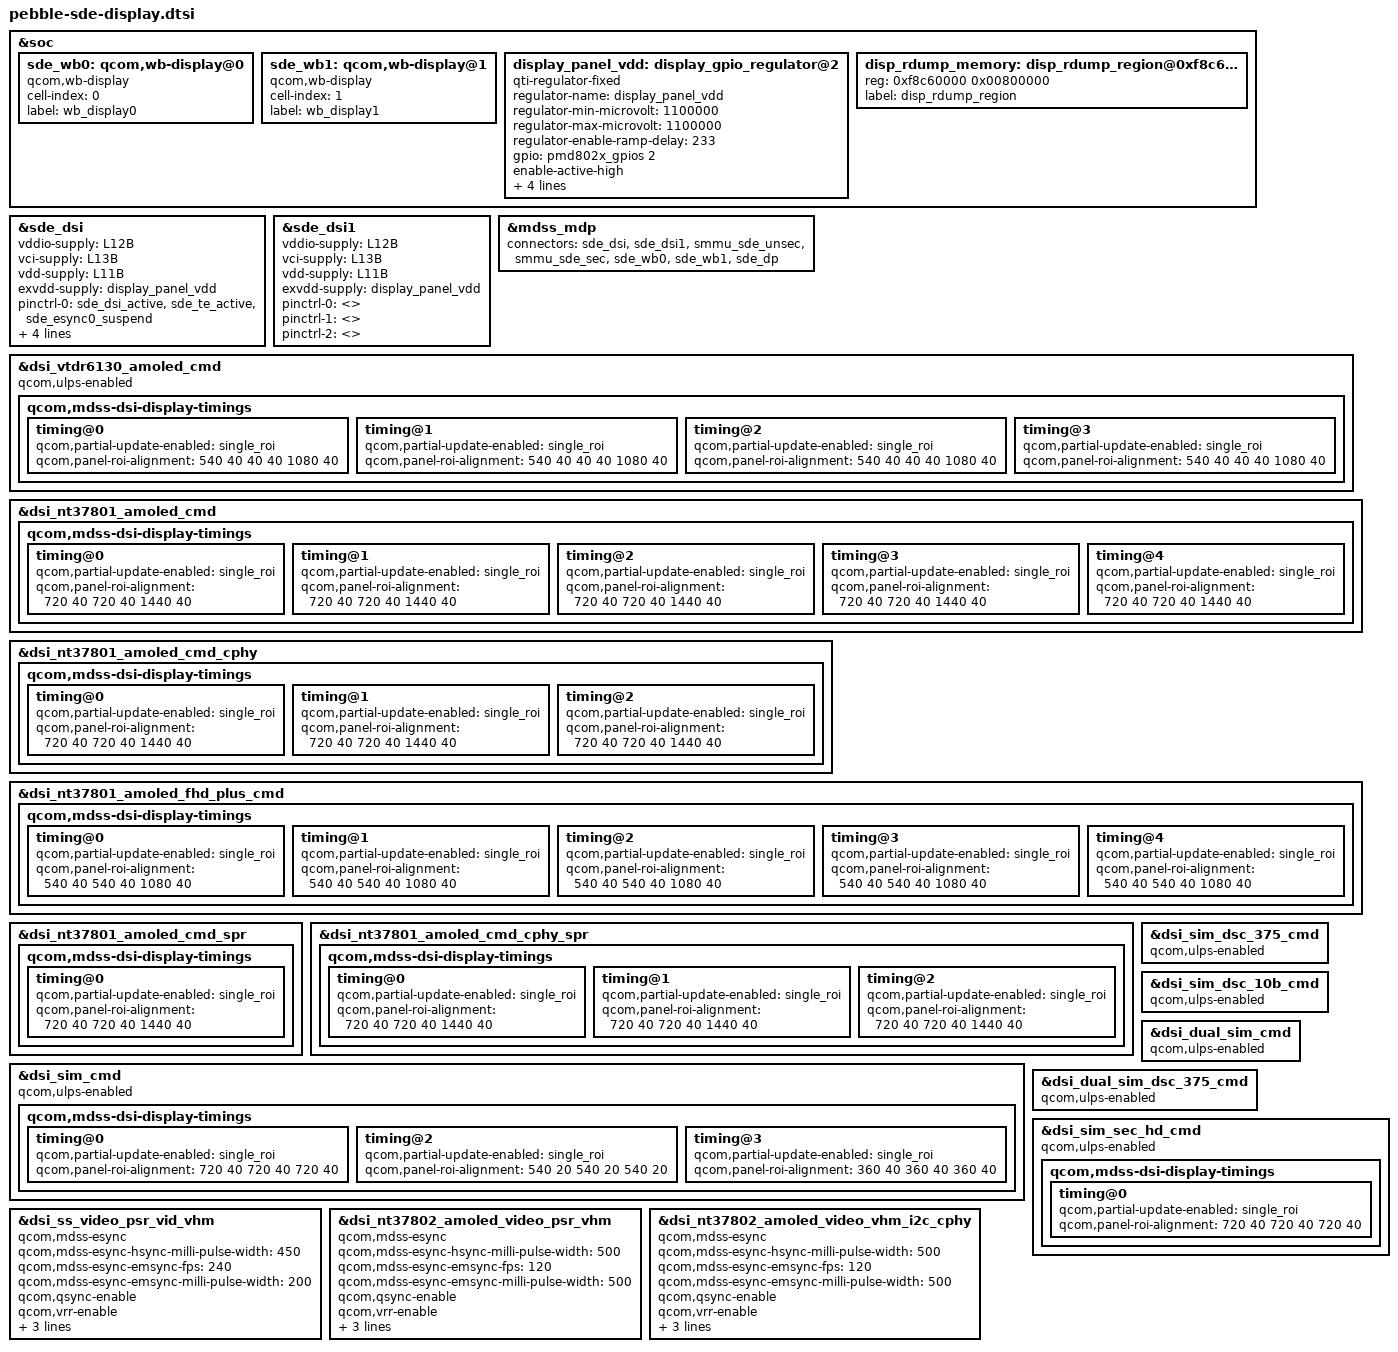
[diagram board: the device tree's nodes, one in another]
// SPDX-License-Identifier: BSD-3-Clause
/*
 * Copyright (c) Qualcomm Technologies, Inc. and/or its subsidiaries.
 */

#include "pebble-sde-display-pinctrl.dtsi"
#include "pebble-sde.dtsi"
#include "pebble-sde-display-common.dtsi"

&soc {
	sde_wb0: qcom,wb-display@0 {
		compatible = "qcom,wb-display";
		cell-index = <0>;
		label = "wb_display0";
	};

	sde_wb1: qcom,wb-display@1 {
		compatible = "qcom,wb-display";
		cell-index = <1>;
		label = "wb_display1";
	};

	display_panel_vdd: display_gpio_regulator@2 {
		compatible = "qti-regulator-fixed";
		regulator-name = "display_panel_vdd";
		regulator-min-microvolt = <1100000>;
		regulator-max-microvolt = <1100000>;
		regulator-enable-ramp-delay = <233>;
		gpio = <&pmd802x_gpios 2 0>;
		enable-active-high;
		regulator-boot-on;
		proxy-supply = <&display_panel_vdd>;
		qcom,proxy-consumer-enable;
		pinctrl-names = "default";
		pinctrl-0 = <&sde_disp0_vdd_active>;
	};

	disp_rdump_memory: disp_rdump_region@0xf8c600000 {
		#address-cells = <1>;
		#size-cells = <1>;
		reg = <0xf8c60000 0x00800000>;
		label = "disp_rdump_region";
	};
};

&sde_dsi {
	vddio-supply = <&L12B>;
	vci-supply = <&L13B>;
	vdd-supply = <&L11B>;
	exvdd-supply = <&display_panel_vdd>;

	pinctrl-names = "panel_active", "panel_active_with_esync", "panel_suspend";
	pinctrl-0 = <&sde_dsi_active &sde_te_active &sde_esync0_suspend>;
	pinctrl-1 = <&sde_dsi_active &sde_te_active &sde_esync0_active>;
	pinctrl-2 = <&sde_dsi_suspend &sde_te_suspend &sde_esync0_suspend>;
};

&sde_dsi1 {
	vddio-supply = <&L12B>;
	vci-supply = <&L13B>;
	vdd-supply = <&L11B>;
	exvdd-supply = <&display_panel_vdd>;

	pinctrl-names = "panel_active", "panel_active_with_esync", "panel_suspend";
	pinctrl-0 = <>;
	pinctrl-1 = <>;
	pinctrl-2 = <>;
};

&mdss_mdp {
	connectors = <&sde_dsi &sde_dsi1 &smmu_sde_unsec &smmu_sde_sec &sde_wb0 &sde_wb1 &sde_dp>;
};

&dsi_vtdr6130_amoled_cmd {
	qcom,ulps-enabled;
	qcom,mdss-dsi-display-timings {
		timing@0 {
			qcom,partial-update-enabled = "single_roi";
			qcom,panel-roi-alignment = <540 40 40 40 1080 40>;
		};

		timing@1 {
			qcom,partial-update-enabled = "single_roi";
			qcom,panel-roi-alignment = <540 40 40 40 1080 40>;
		};

		timing@2 {
			qcom,partial-update-enabled = "single_roi";
			qcom,panel-roi-alignment = <540 40 40 40 1080 40>;
		};

		timing@3 {
			qcom,partial-update-enabled = "single_roi";
			qcom,panel-roi-alignment = <540 40 40 40 1080 40>;
		};
	};
};

&dsi_nt37801_amoled_cmd {
	qcom,mdss-dsi-display-timings {
		timing@0 {
			qcom,partial-update-enabled = "single_roi";
			qcom,panel-roi-alignment = <720 40 720 40 1440 40>;
		};

		timing@1 {
			qcom,partial-update-enabled = "single_roi";
			qcom,panel-roi-alignment = <720 40 720 40 1440 40>;
		};

		timing@2 {
			qcom,partial-update-enabled = "single_roi";
			qcom,panel-roi-alignment = <720 40 720 40 1440 40>;
		};

		timing@3 {
			qcom,partial-update-enabled = "single_roi";
			qcom,panel-roi-alignment = <720 40 720 40 1440 40>;
		};

		timing@4 {
			qcom,partial-update-enabled = "single_roi";
			qcom,panel-roi-alignment = <720 40 720 40 1440 40>;
		};
	};
};

&dsi_nt37801_amoled_cmd_cphy {
	qcom,mdss-dsi-display-timings {
		timing@0 {
			qcom,partial-update-enabled = "single_roi";
			qcom,panel-roi-alignment = <720 40 720 40 1440 40>;
		};

		timing@1 {
			qcom,partial-update-enabled = "single_roi";
			qcom,panel-roi-alignment = <720 40 720 40 1440 40>;
		};

		timing@2 {
			qcom,partial-update-enabled = "single_roi";
			qcom,panel-roi-alignment = <720 40 720 40 1440 40>;
		};
	};
};

&dsi_nt37801_amoled_fhd_plus_cmd {
	qcom,mdss-dsi-display-timings {
		timing@0 {
			qcom,partial-update-enabled = "single_roi";
			qcom,panel-roi-alignment = <540 40 540 40 1080 40>;
		};

		timing@1 {
			qcom,partial-update-enabled = "single_roi";
			qcom,panel-roi-alignment = <540 40 540 40 1080 40>;
		};

		timing@2 {
			qcom,partial-update-enabled = "single_roi";
			qcom,panel-roi-alignment = <540 40 540 40 1080 40>;
		};

		timing@3 {
			qcom,partial-update-enabled = "single_roi";
			qcom,panel-roi-alignment = <540 40 540 40 1080 40>;
		};

		timing@4 {
			qcom,partial-update-enabled = "single_roi";
			qcom,panel-roi-alignment = <540 40 540 40 1080 40>;
		};
	};
};

&dsi_nt37801_amoled_cmd_spr {
	qcom,mdss-dsi-display-timings {
		timing@0 {
			qcom,partial-update-enabled = "single_roi";
			qcom,panel-roi-alignment = <720 40 720 40 1440 40>;
		};
	};
};

&dsi_nt37801_amoled_cmd_cphy_spr {
	qcom,mdss-dsi-display-timings {
		timing@0 {
			qcom,partial-update-enabled = "single_roi";
			qcom,panel-roi-alignment = <720 40 720 40 1440 40>;
		};

		timing@1 {
			qcom,partial-update-enabled = "single_roi";
			qcom,panel-roi-alignment = <720 40 720 40 1440 40>;
		};

		timing@2 {
			qcom,partial-update-enabled = "single_roi";
			qcom,panel-roi-alignment = <720 40 720 40 1440 40>;
		};
	};
};

&dsi_sim_cmd {
	qcom,ulps-enabled;
	qcom,mdss-dsi-display-timings {
		timing@0 { /* WQHD 60FPS cmd vid mode*/
			qcom,partial-update-enabled = "single_roi";
			qcom,panel-roi-alignment = <720 40 720 40 720 40>;
		};

		timing@2 { /* FHD 60FPS cmd mode*/
			qcom,partial-update-enabled = "single_roi";
			qcom,panel-roi-alignment = <540 20 540 20 540 20>;
		};

		timing@3 { /* HD 60FPS cmd mode*/
			qcom,partial-update-enabled = "single_roi";
			qcom,panel-roi-alignment = <360 40 360 40 360 40>;
		};
	};
};

&dsi_sim_dsc_375_cmd {
	qcom,ulps-enabled;
};

&dsi_sim_dsc_10b_cmd {
	qcom,ulps-enabled;
};

&dsi_dual_sim_cmd {
	qcom,ulps-enabled;
};

&dsi_dual_sim_dsc_375_cmd {
	qcom,ulps-enabled;
};

&dsi_sim_sec_hd_cmd {
	qcom,ulps-enabled;
	qcom,mdss-dsi-display-timings {
		timing@0 {
			qcom,partial-update-enabled = "single_roi";
			qcom,panel-roi-alignment = <720 40 720 40 720 40>;
		};
	};
};

&dsi_ss_video_psr_vid_vhm {
	qcom,mdss-esync;
	qcom,mdss-esync-hsync-milli-pulse-width = <450>;
	qcom,mdss-esync-emsync-fps = <240>;
	qcom,mdss-esync-emsync-milli-pulse-width = <200>;

	qcom,qsync-enable;
	qcom,vrr-enable;
	qcom,video-psr-enable;
	qcom,dsi-qsync-avr-step-fps = <240>;
	qcom,mdss-dsi-qsync-min-refresh-rate = <60>;
};

&dsi_nt37802_amoled_video_psr_vhm {
	qcom,mdss-esync;
	qcom,mdss-esync-hsync-milli-pulse-width = <500>;
	qcom,mdss-esync-emsync-fps = <120>;
	qcom,mdss-esync-emsync-milli-pulse-width = <500>;

	qcom,qsync-enable;
	qcom,vrr-enable;
	qcom,video-psr-enable;
	qcom,dsi-qsync-avr-step-fps = <120>;
	qcom,mdss-dsi-qsync-min-refresh-rate = <1>;
};

&dsi_nt37802_amoled_video_vhm_i2c_cphy {
	qcom,mdss-esync;
	qcom,mdss-esync-hsync-milli-pulse-width = <500>;
	qcom,mdss-esync-emsync-fps = <120>;
	qcom,mdss-esync-emsync-milli-pulse-width = <500>;

	qcom,qsync-enable;
	qcom,vrr-enable;
	qcom,video-psr-enable;
	qcom,dsi-qsync-avr-step-fps = <120>;
	qcom,mdss-dsi-qsync-min-refresh-rate = <1>;
};
